AUTOSAR XML (schema 3.1.2)
package /Components/SWC_CurDrivFil
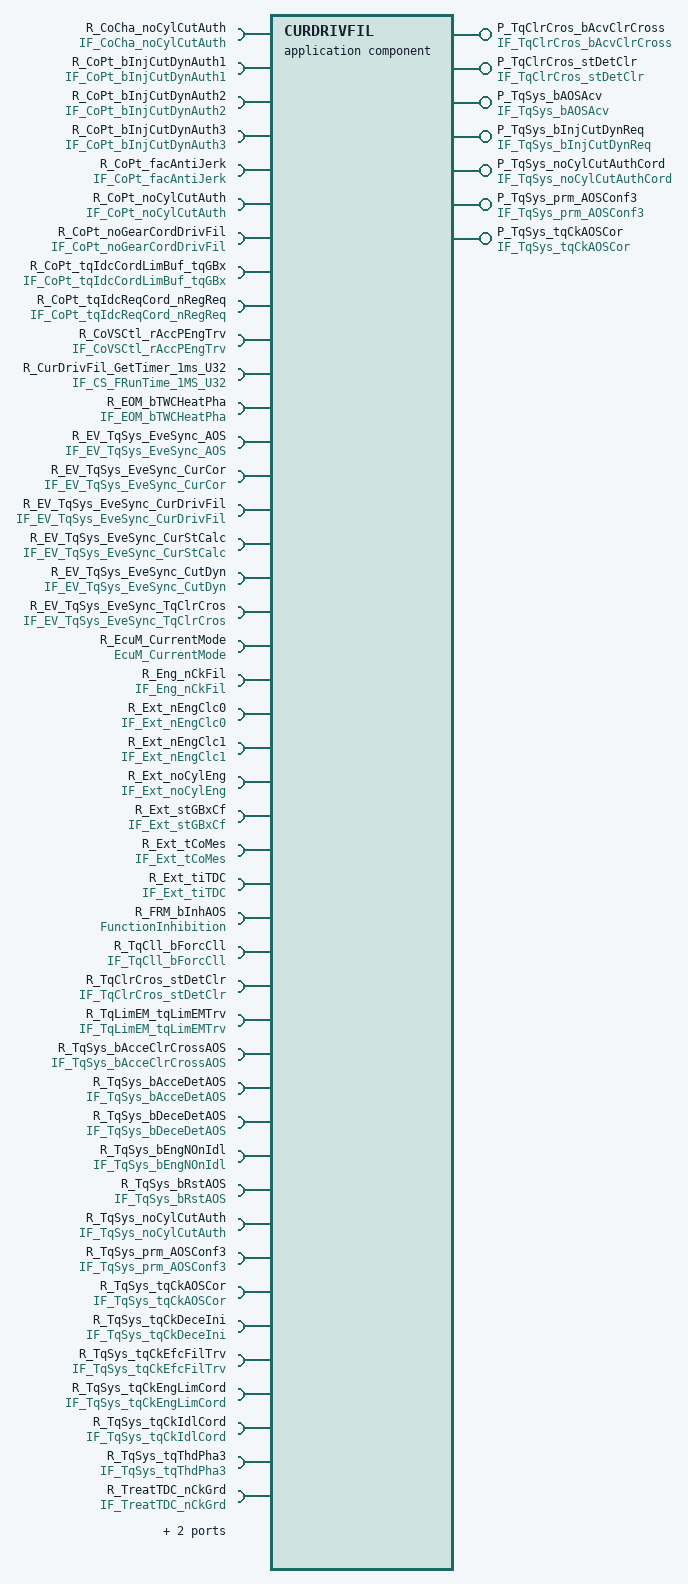
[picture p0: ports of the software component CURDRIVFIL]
  application software component type CURDRIVFIL  # CurDrivFil
    7 x provide port:
      P_TqClrCros_bAcvClrCross: unqueued-sender-com-spec{data-element=TqClrCros_bAcvClrCross, can-invalidate=false, init-value=ConstantValue}, provided-interface=IF_TqClrCros_bAcvClrCross  # Requirement: 01552_10_01787-CurDrivFil.I127(0)
      P_TqClrCros_stDetClr: unqueued-sender-com-spec{data-element=TqClrCros_stDetClr, can-invalidate=false, init-value=ConstantValue1}, provided-interface=IF_TqClrCros_stDetClr  # Requirement: 01552_10_01787-CurDrivFil.I128(0)
      P_TqSys_bAOSAcv: unqueued-sender-com-spec{data-element=TqSys_bAOSAcv, can-invalidate=false, init-value=ConstantValue3}, provided-interface=IF_TqSys_bAOSAcv  # Requirement: 01552_10_01787-CurDrivFil.I145(1)
      P_TqSys_bInjCutDynReq: unqueued-sender-com-spec{data-element=TqSys_bInjCutDynReq, can-invalidate=false, init-value=ConstantValue5}, provided-interface=IF_TqSys_bInjCutDynReq  # Requirement: 01552_10_01787-CurDrivFil.I132(1)
      P_TqSys_noCylCutAuthCord: unqueued-sender-com-spec{data-element=TqSys_noCylCutAuthCord, can-invalidate=false, init-value=ConstantValue7}, provided-interface=IF_TqSys_noCylCutAuthCord  # Requirement: 01552_10_01787-CurDrivFil.I131(1)
      P_TqSys_prm_AOSConf3: unqueued-sender-com-spec{data-element=TqSys_prm_AOSConf3, can-invalidate=false, init-value=ArrayConstantValue}, provided-interface=IF_TqSys_prm_AOSConf3  # Requirement: 01552_10_01787-CurDrivFil.I413(2)
      P_TqSys_tqCkAOSCor: unqueued-sender-com-spec{data-element=TqSys_tqCkAOSCor, can-invalidate=false, init-value=ConstantValue9}, provided-interface=IF_TqSys_tqCkAOSCor  # Requirement: 01552_10_01787-CurDrivFil.I146(1)
    46 x require port:
      R_CoCha_noCylCutAuth: unqueued-receiver-com-spec{data-element=CoCha_noCylCutAuth, init-value=ConstantValue11, resync-time=0}, required-interface=IF_CoCha_noCylCutAuth  # Requirement: 01552_10_01787-CurDrivFil.I133(0)
      R_CoPt_bInjCutDynAuth1: unqueued-receiver-com-spec{data-element=CoPt_bInjCutDynAuth1, init-value=ConstantValue13, resync-time=0}, required-interface=IF_CoPt_bInjCutDynAuth1  # Requirement: 01552_10_01787-CurDrivFil.I134(0)
      R_CoPt_bInjCutDynAuth2: unqueued-receiver-com-spec{data-element=CoPt_bInjCutDynAuth2, init-value=ConstantValue15, resync-time=0}, required-interface=IF_CoPt_bInjCutDynAuth2  # Requirement: 01552_10_01787-CurDrivFil.I135(0)
      R_CoPt_bInjCutDynAuth3: unqueued-receiver-com-spec{data-element=CoPt_bInjCutDynAuth3, init-value=ConstantValue17, resync-time=0}, required-interface=IF_CoPt_bInjCutDynAuth3  # Requirement: 01552_10_01787-CurDrivFil.I136(0)
      R_CoPt_facAntiJerk: unqueued-receiver-com-spec{data-element=CoPt_facAntiJerk, init-value=ConstantValue19, resync-time=0}, required-interface=IF_CoPt_facAntiJerk  # Requirement: 01552_10_01787-CurDrivFil.I100(0)
      R_CoPt_noCylCutAuth: unqueued-receiver-com-spec{data-element=CoPt_noCylCutAuth, init-value=ConstantValue21, resync-time=0}, required-interface=IF_CoPt_noCylCutAuth  # Requirement: 01552_10_01787-CurDrivFil.I137(0)
      R_CoPt_noGearCordDrivFil: unqueued-receiver-com-spec{data-element=CoPt_noGearCordDrivFil, init-value=ConstantValue23, resync-time=0}, required-interface=IF_CoPt_noGearCordDrivFil  # Requirement: 01552_10_01787-CurDrivFil.I119(0)
      R_CoPt_tqIdcCordLimBuf_tqGBx: unqueued-receiver-com-spec{data-element=CoPt_tqIdcCordLimBuf_tqGBx, init-value=ConstantValue25, resync-time=0}, required-interface=IF_CoPt_tqIdcCordLimBuf_tqGBx  # Requirement: 01552_10_01787-CurDrivFil.I138(0)
      R_CoPt_tqIdcReqCord_nRegReq: unqueued-receiver-com-spec{data-element=CoPt_tqIdcReqCord_nRegReq, init-value=ConstantValue27, resync-time=0}, required-interface=IF_CoPt_tqIdcReqCord_nRegReq  # Requirement: 01552_10_01787-CurDrivFil.I105(0)
      R_CoVSCtl_rAccPEngTrv: unqueued-receiver-com-spec{data-element=CoVSCtl_rAccPEngTrv, init-value=ConstantValue29, resync-time=0}, required-interface=IF_CoVSCtl_rAccPEngTrv  # Requirement: 01552_10_01787-CurDrivFil.I120(0)
      R_CurDrivFil_GetTimer_1ms_U32: required-interface=IF_CS_FRunTime_1MS_U32
      R_EOM_bTWCHeatPha: unqueued-receiver-com-spec{data-element=EOM_bTWCHeatPha, init-value=ConstantValue31, resync-time=0}, required-interface=IF_EOM_bTWCHeatPha  # Requirement: 01552_10_01787-CurDrivFil.I121(0)
      R_EV_TqSys_EveSync_AOS: unqueued-receiver-com-spec{data-element=EV_TqSys_EveSync_AOS, init-value=ConstantValue33, resync-time=0}, required-interface=IF_EV_TqSys_EveSync_AOS
      R_EV_TqSys_EveSync_CurCor: unqueued-receiver-com-spec{data-element=EV_TqSys_EveSync_CurCor, init-value=ConstantValue35, resync-time=0}, required-interface=IF_EV_TqSys_EveSync_CurCor
      R_EV_TqSys_EveSync_CurDrivFil: unqueued-receiver-com-spec{data-element=EV_TqSys_EveSync_CurDrivFil, init-value=ConstantValue37, resync-time=0}, required-interface=IF_EV_TqSys_EveSync_CurDrivFil
      R_EV_TqSys_EveSync_CurStCalc: unqueued-receiver-com-spec{data-element=EV_TqSys_EveSync_CurStCalc, init-value=ConstantValue39, resync-time=0}, required-interface=IF_EV_TqSys_EveSync_CurStCalc
      R_EV_TqSys_EveSync_CutDyn: unqueued-receiver-com-spec{data-element=EV_TqSys_EveSync_CutDyn, init-value=ConstantValue41, resync-time=0}, required-interface=IF_EV_TqSys_EveSync_CutDyn
      R_EV_TqSys_EveSync_TqClrCros: unqueued-receiver-com-spec{data-element=EV_TqSys_EveSync_TqClrCros, init-value=ConstantValue43, resync-time=0}, required-interface=IF_EV_TqSys_EveSync_TqClrCros
      R_EcuM_CurrentMode: required-interface=EcuM_CurrentMode  # Requirement: 01552_09_00532-SSTG-C007(0)
      R_Eng_nCkFil: unqueued-receiver-com-spec{data-element=Eng_nCkFil, init-value=ConstantValue45, resync-time=0}, required-interface=IF_Eng_nCkFil  # Requirement: 01552_10_01787-CurDrivFil.I139(0)
      R_Ext_nEngClc0: unqueued-receiver-com-spec{data-element=Ext_nEngClc0, init-value=ConstantValue47, resync-time=0}, required-interface=IF_Ext_nEngClc0  # Requirement: 01552_10_01787-CurDrivFil.I102(0)
      R_Ext_nEngClc1: unqueued-receiver-com-spec{data-element=Ext_nEngClc1, init-value=ConstantValue49, resync-time=0}, required-interface=IF_Ext_nEngClc1  # Requirement: 01552_10_01787-CurDrivFil.I103(0)
      R_Ext_noCylEng: unqueued-receiver-com-spec{data-element=Ext_noCylEng, init-value=ConstantValue51, resync-time=0}, required-interface=IF_Ext_noCylEng  # Requirement: 01552_10_01787-CurDrivFil.I140(0)
      R_Ext_stGBxCf: unqueued-receiver-com-spec{data-element=Ext_stGBxCf, init-value=ConstantValue53, resync-time=0}, required-interface=IF_Ext_stGBxCf  # Requirement: 01552_10_01787-CurDrivFil.I101(0)
      R_Ext_tCoMes: unqueued-receiver-com-spec{data-element=Ext_tCoMes, init-value=ConstantValue55, resync-time=0}, required-interface=IF_Ext_tCoMes  # Requirement: 01552_10_01787-CurDrivFil.I112(0)
      R_Ext_tiTDC: unqueued-receiver-com-spec{data-element=Ext_tiTDC, init-value=ConstantValue57, resync-time=0}, required-interface=IF_Ext_tiTDC  # Requirement: 01552_10_01787-CurDrivFil.I113(0)
      R_FRM_bInhAOS: required-interface=FunctionInhibition  # Requirement: 01552_10_01787-CurDrivFil.I700(0)
      R_TqCll_bForcCll: unqueued-receiver-com-spec{data-element=TqCll_bForcCll, init-value=ConstantValue59, resync-time=0}, required-interface=IF_TqCll_bForcCll  # Requirement: 01552_10_01787-CurDrivFil.I141(0)
      R_TqClrCros_stDetClr: unqueued-receiver-com-spec{data-element=TqClrCros_stDetClr, init-value=ConstantValue61, resync-time=0}, required-interface=IF_TqClrCros_stDetClr  # Requirement: 01552_10_01787-CurDrivFil.I156(0)
      R_TqLimEM_tqLimEMTrv: unqueued-receiver-com-spec{data-element=TqLimEM_tqLimEMTrv, init-value=ConstantValue63, resync-time=0}, required-interface=IF_TqLimEM_tqLimEMTrv  # Requirement: 01552_10_01787-CurDrivFil.I155(1)
      R_TqSys_bAcceClrCrossAOS: unqueued-receiver-com-spec{data-element=TqSys_bAcceClrCrossAOS, init-value=ConstantValue65, resync-time=0}, required-interface=IF_TqSys_bAcceClrCrossAOS  # Requirement: 01552_10_01787-CurDrivFil.I124(0)
      R_TqSys_bAcceDetAOS: unqueued-receiver-com-spec{data-element=TqSys_bAcceDetAOS, init-value=ConstantValue67, resync-time=0}, required-interface=IF_TqSys_bAcceDetAOS  # Requirement: 01552_10_01787-CurDrivFil.I125(0)
      R_TqSys_bDeceDetAOS: unqueued-receiver-com-spec{data-element=TqSys_bDeceDetAOS, init-value=ConstantValue69, resync-time=0}, required-interface=IF_TqSys_bDeceDetAOS  # Requirement: 01552_10_01787-CurDrivFil.I126(0)
      R_TqSys_bEngNOnIdl: unqueued-receiver-com-spec{data-element=TqSys_bEngNOnIdl, init-value=ConstantValue71, resync-time=0}, required-interface=IF_TqSys_bEngNOnIdl  # Requirement: 01552_10_01787-CurDrivFil.I109(0)
      R_TqSys_bRstAOS: unqueued-receiver-com-spec{data-element=TqSys_bRstAOS, init-value=ConstantValue73, resync-time=0}, required-interface=IF_TqSys_bRstAOS  # Requirement: 01552_10_01787-CurDrivFil.I147(0)
      R_TqSys_noCylCutAuth: unqueued-receiver-com-spec{data-element=TqSys_noCylCutAuth, init-value=ConstantValue75, resync-time=0}, required-interface=IF_TqSys_noCylCutAuth  # Requirement: 01552_10_01787-CurDrivFil.I143(0)
      R_TqSys_prm_AOSConf3: unqueued-receiver-com-spec{data-element=TqSys_prm_AOSConf3, init-value=ArrayConstantValue, resync-time=0}, required-interface=IF_TqSys_prm_AOSConf3  # Requirement: 01552_10_01787-CurDrivFil.I154(0)
      R_TqSys_tqCkAOSCor: unqueued-receiver-com-spec{data-element=TqSys_tqCkAOSCor, init-value=ConstantValue77, resync-time=0}, required-interface=IF_TqSys_tqCkAOSCor  # Requirement: 01552_10_01787-CurDrivFil.I157(0)
      R_TqSys_tqCkDeceIni: unqueued-receiver-com-spec{data-element=TqSys_tqCkDeceIni, init-value=ConstantValue79, resync-time=0}, required-interface=IF_TqSys_tqCkDeceIni  # Requirement: 01552_10_01787-CurDrivFil.I108(0)
      R_TqSys_tqCkEfcFilTrv: unqueued-receiver-com-spec{data-element=TqSys_tqCkEfcFilTrv, init-value=ConstantValue81, resync-time=0}, required-interface=IF_TqSys_tqCkEfcFilTrv  # Requirement: 01552_10_01787-CurDrivFil.I129(0)
      R_TqSys_tqCkEngLimCord: unqueued-receiver-com-spec{data-element=TqSys_tqCkEngLimCord, init-value=ConstantValue83, resync-time=0}, required-interface=IF_TqSys_tqCkEngLimCord  # Requirement: 01552_10_01787-CurDrivFil.I107(1)
      R_TqSys_tqCkIdlCord: unqueued-receiver-com-spec{data-element=TqSys_tqCkIdlCord, init-value=ConstantValue85, resync-time=0}, required-interface=IF_TqSys_tqCkIdlCord  # Requirement: 01552_10_01787-CurDrivFil.I106(0)
      R_TqSys_tqThdPha3: unqueued-receiver-com-spec{data-element=TqSys_tqThdPha3, init-value=ConstantValue87, resync-time=0}, required-interface=IF_TqSys_tqThdPha3  # Requirement: 01552_10_01787-CurDrivFil.I130(0)
      R_TreatTDC_nCkGrd: unqueued-receiver-com-spec{data-element=TreatTDC_nCkGrd, init-value=ConstantValue89, resync-time=0}, required-interface=IF_TreatTDC_nCkGrd  # Requirement: 01552_10_01787-CurDrivFil.I111(0)
      R_UCE_stSt: required-interface=IF_UCE_stSt  # Requirement: 01552_09_00532-SSTG-C011(0)
      R_Veh_spdVeh: unqueued-receiver-com-spec{data-element=Veh_spdVeh, init-value=ConstantValue91, resync-time=0}, required-interface=IF_Veh_spdVeh  # Requirement: 01552_10_01787-CurDrivFil.I104(0)
  64 x constant specification:
    ArrayConstantValue
      value:
        array specification ArrayConstantValue: type=t_CurDrivFil_Tab6_S16
          6 x integer literal, all with type=DT_TqSys_prm_AOSConf3, value=0:
            Const
            Const{1..5}
    C_Boolean_False
      value:
        boolean literal C_Boolean_False: type=DT_TqSys_bAOSSlopAcv_irv, value=false
    C_SInt16_0
      value:
        integer literal C_SInt16_0: type=DT_TqSys_facCorIdlPha_irv, value=0
    C_SInt16_0101
      value:
        integer literal C_SInt16_0101: type=DT_TqSys_facSpd0AOS_irv, value=0
    C_SInt16_0103
      value:
        integer literal C_SInt16_0103: type=DT_TqSys_facTq2AOS_irv, value=0
    C_SInt16_0107
      value:
        integer literal C_SInt16_0107: type=DT_TqSys_facTq3AOS_irv, value=0
    C_SInt16_0109
      value:
        integer literal C_SInt16_0109: type=DT_TqSys_facTq1AOS_irv, value=0
    C_SInt16_0111
      value:
        integer literal C_SInt16_0111: type=DT_TqSys_facTq0AOS_irv, value=0
    C_SInt16_0113
      value:
        integer literal C_SInt16_0113: type=DT_TqSys_tqCkFilRawAOS_irv, value=0
    C_SInt16_0115
      value:
        integer literal C_SInt16_0115: type=DT_TqSys_facCorOxCHeatPha_irv, value=0
    C_SInt16_093
      value:
        integer literal C_SInt16_093: type=DT_TqSys_facSpd1AOS_irv, value=0
    C_SInt16_097
      value:
        integer literal C_SInt16_097: type=DT_TqSys_facCorGlbl_irv, value=0
    C_SInt16_099
      value:
        integer literal C_SInt16_099: type=DT_TqSys_nFil2AOS_irv, value=0
    C_UInt16_0
      value:
        integer literal C_UInt16_0: type=DT_TqSys_ctOfsAcvAOS_irv, value=0
    C_UInt16_0105
      value:
        integer literal C_UInt16_0105: type=DT_TqSys_ctIncAcvAOS_irv, value=0
    C_UInt16_095
      value:
        integer literal C_UInt16_095: type=DT_TqSys_ctIncDiAOS_irv, value=0
    C_UInt8_2
      value:
        integer literal C_UInt8_2: type=DT_TqSys_stAcceAOS_irv, value=2
    ConstantValue
      value:
        boolean literal ConstantValue: type=DT_TqClrCros_bAcvClrCross, value=false
    ConstantValue1
      value:
        integer literal ConstantValue1: type=DT_TqClrCros_stDetClr, value=0
    ConstantValue11
      value:
        integer literal ConstantValue11: type=DT_CoCha_noCylCutAuth, value=0
    ConstantValue13
      value:
        boolean literal ConstantValue13: type=DT_CoPt_bInjCutDynAuth1, value=false
    ConstantValue15
      value:
        boolean literal ConstantValue15: type=DT_CoPt_bInjCutDynAuth2, value=false
    ConstantValue17
      value:
        boolean literal ConstantValue17: type=DT_CoPt_bInjCutDynAuth3, value=false
    ConstantValue19
      value:
        integer literal ConstantValue19: type=DT_CoPt_facAntiJerk, value=0
    ConstantValue21
      value:
        integer literal ConstantValue21: type=DT_CoPt_noCylCutAuth, value=0
    ConstantValue23
      value:
        integer literal ConstantValue23: type=DT_CoPt_noGearCordDrivFil, value=0
    ConstantValue25
      value:
        integer literal ConstantValue25: type=DT_CoPt_tqIdcCordLimBuf_tqGBx, value=0
    ConstantValue27
      value:
        integer literal ConstantValue27: type=DT_CoPt_tqIdcReqCord_nRegReq, value=0
    ConstantValue29
      value:
        integer literal ConstantValue29: type=DT_CoVSCtl_rAccPEngTrv, value=0
    ConstantValue3
      value:
        boolean literal ConstantValue3: type=DT_TqSys_bAOSAcv, value=false
    ConstantValue31
      value:
        boolean literal ConstantValue31: type=DT_EOM_bTWCHeatPha, value=false
    ConstantValue33
      value:
        integer literal ConstantValue33: type=DT_EV_TqSys_EveSync_AOS, value=0
    ConstantValue35
      value:
        integer literal ConstantValue35: type=DT_EV_TqSys_EveSync_CurCor, value=0
    ConstantValue37
      value:
        integer literal ConstantValue37: type=DT_EV_TqSys_EveSync_CurDrivFil, value=0
    ConstantValue39
      value:
        integer literal ConstantValue39: type=DT_EV_TqSys_EveSync_CurStCalc, value=0
    ConstantValue41
      value:
        integer literal ConstantValue41: type=DT_EV_TqSys_EveSync_CutDyn, value=0
    ConstantValue43
      value:
        integer literal ConstantValue43: type=DT_EV_TqSys_EveSync_TqClrCros, value=0
    ConstantValue45
      value:
        integer literal ConstantValue45: type=DT_Eng_nCkFil, value=0
    ConstantValue47
      value:
        integer literal ConstantValue47: type=DT_Ext_nEngClc0, value=0
    ConstantValue49
      value:
        integer literal ConstantValue49: type=DT_Ext_nEngClc1, value=0
    ConstantValue5
      value:
        boolean literal ConstantValue5: type=DT_TqSys_bInjCutDynReq, value=false
    ConstantValue51
      value:
        integer literal ConstantValue51: type=DT_Ext_noCylEng, value=1
    ConstantValue53
      value:
        integer literal ConstantValue53: type=DT_Ext_stGBxCf, value=0
    ConstantValue55
      value:
        integer literal ConstantValue55: type=DT_Ext_tCoMes, value=20
    ConstantValue57
      value:
        integer literal ConstantValue57: type=DT_Ext_tiTDC, value=100
    ConstantValue59
      value:
        boolean literal ConstantValue59: type=DT_TqCll_bForcCll, value=false
    ConstantValue61
      value:
        integer literal ConstantValue61: type=DT_TqClrCros_stDetClr, value=0
    ConstantValue63
      value:
        integer literal ConstantValue63: type=DT_TqLimEM_tqLimEMTrv, value=0
    ConstantValue65
      value:
        boolean literal ConstantValue65: type=DT_TqSys_bAcceClrCrossAOS, value=false
    ConstantValue67
      value:
        boolean literal ConstantValue67: type=DT_TqSys_bAcceDetAOS, value=false
    ConstantValue69
      value:
        boolean literal ConstantValue69: type=DT_TqSys_bDeceDetAOS, value=false
    ConstantValue7
      value:
        integer literal ConstantValue7: type=DT_TqSys_noCylCutAuthCord, value=0
    ConstantValue71
      value:
        boolean literal ConstantValue71: type=DT_TqSys_bEngNOnIdl, value=true
    ConstantValue73
      value:
        boolean literal ConstantValue73: type=DT_TqSys_bRstAOS, value=false
    ConstantValue75
      value:
        integer literal ConstantValue75: type=DT_TqSys_noCylCutAuth, value=0
    ConstantValue77
      value:
        integer literal ConstantValue77: type=DT_TqSys_tqCkAOSCor, value=0
    ConstantValue79
      value:
        integer literal ConstantValue79: type=DT_TqSys_tqCkDeceIni, value=0
    ConstantValue81
      value:
        integer literal ConstantValue81: type=DT_TqSys_tqCkEfcFilTrv, value=0
    ConstantValue83
      value:
        integer literal ConstantValue83: type=DT_TqSys_tqCkEngLimCord, value=0
    ConstantValue85
      value:
        integer literal ConstantValue85: type=DT_TqSys_tqCkIdlCord, value=0
    ConstantValue87
      value:
        integer literal ConstantValue87: type=DT_TqSys_tqThdPha3, value=0
    ConstantValue89
      value:
        integer literal ConstantValue89: type=DT_TreatTDC_nCkGrd, value=0
    ConstantValue9
      value:
        integer literal ConstantValue9: type=DT_TqSys_tqCkAOSCor, value=0
    ConstantValue91
      value:
        integer literal ConstantValue91: type=DT_Veh_spdVeh, value=0
  internal behavior IB_CurDrivFil: component=CURDRIVFIL
    mode switch event EV_CurDrivFil_001_MSE: start-on-event=RE_CurDrivFil_001_MSE, activation=ENTRY, mode=R_EcuM_CurrentMode.currentMode.RUN
    6 x data received event, all with mode-dependency=dependent-on-mode=[R_UCE_stSt.RCD_Mode.COM_LATCH, R_UCE_stSt.RCD_Mode.INTERNAL_PARTIAL_WAKEUP, R_UCE_stSt.RCD_Mode.INTERNAL_PARTIAL_WAKEUP_APC, R_UCE_stSt.RCD_Mode.PARTIAL_WAKEUP, R_UCE_stSt.RCD_Mode.SHUTDOWN_PREPARATION, R_UCE_stSt.RCD_Mode.SHUTDOWN_PREPARATION_APC, R_UCE_stSt.RCD_Mode.TRANSITORY]:
      EV_TqSys_EveSync_CutDyn: start-on-event=RE_TqSys_EveSync_CutDyn, data=R_EV_TqSys_EveSync_CutDyn.EV_TqSys_EveSync_CutDyn
      EV_TqSys_EveSync_CurCor: start-on-event=RE_TqSys_EveSync_CurCor, data=R_EV_TqSys_EveSync_CurCor.EV_TqSys_EveSync_CurCor
      EV_TqSys_EveSync_TqClrCros: start-on-event=RE_TqSys_EveSync_TqClrCros, data=R_EV_TqSys_EveSync_TqClrCros.EV_TqSys_EveSync_TqClrCros
      EV_TqSys_EveSync_AOS: start-on-event=RE_TqSys_EveSync_AOS, data=R_EV_TqSys_EveSync_AOS.EV_TqSys_EveSync_AOS
      EV_TqSys_EveSync_CurStCalc: start-on-event=RE_TqSys_EveSync_CurStCalc, data=R_EV_TqSys_EveSync_CurStCalc.EV_TqSys_EveSync_CurStCalc
      EV_TqSys_EveSync_CurDrivFil: start-on-event=RE_TqSys_EveSync_CurDrivFil, data=R_EV_TqSys_EveSync_CurDrivFil.EV_TqSys_EveSync_CurDrivFil
    16 x inter runnable variable, all with sw-calibration-access=READ-WRITE, communication-approach=EXPLICIT:
      TqSys_ctOfsAcvAOS_irv: type=DT_TqSys_ctOfsAcvAOS_irv, init-value=C_UInt16_0
      TqSys_ctIncAcvAOS_irv: type=DT_TqSys_ctIncAcvAOS_irv, init-value=C_UInt16_0105
      TqSys_facTq2AOS_irv: type=DT_TqSys_facTq2AOS_irv, init-value=C_SInt16_0103
      TqSys_bAOSSlopAcv_irv: type=DT_TqSys_bAOSSlopAcv_irv, init-value=C_Boolean_False
      TqSys_tqCkFilRawAOS_irv: type=DT_TqSys_tqCkFilRawAOS_irv, init-value=C_SInt16_0113
      TqSys_facTq3AOS_irv: type=DT_TqSys_facTq3AOS_irv, init-value=C_SInt16_0107
      TqSys_nFil2AOS_irv: type=DT_TqSys_nFil2AOS_irv, init-value=C_SInt16_099
      TqSys_facCorIdlPha_irv: type=DT_TqSys_facCorIdlPha_irv, init-value=C_SInt16_0
      TqSys_facTq1AOS_irv: type=DT_TqSys_facTq1AOS_irv, init-value=C_SInt16_0109
      TqSys_ctIncDiAOS_irv: type=DT_TqSys_ctIncDiAOS_irv, init-value=C_UInt16_095
      TqSys_facCorGlbl_irv: type=DT_TqSys_facCorGlbl_irv, init-value=C_SInt16_097
      TqSys_stAcceAOS_irv: type=DT_TqSys_stAcceAOS_irv, init-value=C_UInt8_2
      TqSys_facCorOxCHeatPha_irv: type=DT_TqSys_facCorOxCHeatPha_irv, init-value=C_SInt16_0115
      TqSys_facSpd0AOS_irv: type=DT_TqSys_facSpd0AOS_irv, init-value=C_SInt16_0101
      TqSys_facSpd1AOS_irv: type=DT_TqSys_facSpd1AOS_irv, init-value=C_SInt16_093
      TqSys_facTq0AOS_irv: type=DT_TqSys_facTq0AOS_irv, init-value=C_SInt16_0111
    7 x runnable:
      RE_TqSys_EveSync_CurStCalc: read-variable=TqSys_nFil2AOS_irv, written-variable=[TqSys_nFil2AOS_irv, TqSys_stAcceAOS_irv]
        12 x data receive point:
          dr_TqSys_bAcceDetAOS: data-element=R_TqSys_bAcceDetAOS.TqSys_bAcceDetAOS
          dr_TqSys_bDeceDetAOS: data-element=R_TqSys_bDeceDetAOS.TqSys_bDeceDetAOS
          dr_TqSys_tqThdPha3: data-element=R_TqSys_tqThdPha3.TqSys_tqThdPha3
          dr_TqSys_tqCkDeceIni: data-element=R_TqSys_tqCkDeceIni.TqSys_tqCkDeceIni
          dr_TqLimEM_tqLimEMTrv: data-element=R_TqLimEM_tqLimEMTrv.TqLimEM_tqLimEMTrv
          dr_Ext_tiTDC: data-element=R_Ext_tiTDC.Ext_tiTDC
          dr_TqSys_bAcceClrCrossAOS: data-element=R_TqSys_bAcceClrCrossAOS.TqSys_bAcceClrCrossAOS
          dr_TqClrCros_stDetClr: data-element=R_TqClrCros_stDetClr.TqClrCros_stDetClr
          dr_CoPt_noGearCordDrivFil: data-element=R_CoPt_noGearCordDrivFil.CoPt_noGearCordDrivFil
          dr_TqSys_tqCkAOSCor: data-element=R_TqSys_tqCkAOSCor.TqSys_tqCkAOSCor
          dr_Ext_nEngClc0: data-element=R_Ext_nEngClc0.Ext_nEngClc0
          dr_TqSys_tqCkEfcFilTrv: data-element=R_TqSys_tqCkEfcFilTrv.TqSys_tqCkEfcFilTrv
        sync call ssp_GetTimer_1ms_U32: operation=R_CurDrivFil_GetTimer_1ms_U32.GetTimer_1ms_U32
      RE_CurDrivFil_001_MSE: written-variable=[TqSys_facCorIdlPha_irv, TqSys_facTq0AOS_irv, TqSys_facTq2AOS_irv, TqSys_stAcceAOS_irv, TqSys_ctOfsAcvAOS_irv, TqSys_facTq1AOS_irv, TqSys_bAOSSlopAcv_irv, TqSys_nFil2AOS_irv, TqSys_tqCkFilRawAOS_irv, TqSys_facCorGlbl_irv, TqSys_facTq3AOS_irv, TqSys_facSpd1AOS_irv, TqSys_ctIncDiAOS_irv, TqSys_facSpd0AOS_irv, TqSys_facCorOxCHeatPha_irv, TqSys_ctIncAcvAOS_irv]  # RE_062095_10ms_init
        7 x data send point:
          ds_TqSys_bInjCutDynReq: data-element=P_TqSys_bInjCutDynReq.TqSys_bInjCutDynReq
          ds_TqSys_tqCkAOSCor: data-element=P_TqSys_tqCkAOSCor.TqSys_tqCkAOSCor
          ds_TqClrCros_bAcvClrCross: data-element=P_TqClrCros_bAcvClrCross.TqClrCros_bAcvClrCross
          ds_TqClrCros_stDetClr: data-element=P_TqClrCros_stDetClr.TqClrCros_stDetClr
          ds_TqSys_bAOSAcv: data-element=P_TqSys_bAOSAcv.TqSys_bAOSAcv
          ds_TqSys_prm_AOSConf3: data-element=P_TqSys_prm_AOSConf3.TqSys_prm_AOSConf3
          ds_TqSys_noCylCutAuthCord: data-element=P_TqSys_noCylCutAuthCord.TqSys_noCylCutAuthCord
        sync call ssp_GetTimer_1ms_U32: operation=R_CurDrivFil_GetTimer_1ms_U32.GetTimer_1ms_U32
      RE_TqSys_EveSync_CurDrivFil: read-variable=[TqSys_facCorGlbl_irv, TqSys_stAcceAOS_irv], written-variable=[TqSys_facTq2AOS_irv, TqSys_facCorGlbl_irv, TqSys_ctOfsAcvAOS_irv, TqSys_facTq3AOS_irv, TqSys_facTq0AOS_irv, TqSys_facCorIdlPha_irv, TqSys_facSpd0AOS_irv, TqSys_facTq1AOS_irv, TqSys_stAcceAOS_irv, TqSys_facSpd1AOS_irv, TqSys_ctIncDiAOS_irv, TqSys_ctIncAcvAOS_irv, TqSys_facCorOxCHeatPha_irv, TqSys_bAOSSlopAcv_irv]
        11 x data receive point:
          dr_TqSys_tqCkDeceIni: data-element=R_TqSys_tqCkDeceIni.TqSys_tqCkDeceIni
          dr_Veh_spdVeh: data-element=R_Veh_spdVeh.Veh_spdVeh
          dr_CoPt_noGearCordDrivFil: data-element=R_CoPt_noGearCordDrivFil.CoPt_noGearCordDrivFil
          dr_TreatTDC_nCkGrd: data-element=R_TreatTDC_nCkGrd.TreatTDC_nCkGrd
          dr_TqSys_prm_AOSConf3: data-element=R_TqSys_prm_AOSConf3.TqSys_prm_AOSConf3
          dr_EOM_bTWCHeatPha: data-element=R_EOM_bTWCHeatPha.EOM_bTWCHeatPha
          dr_Ext_nEngClc0: data-element=R_Ext_nEngClc0.Ext_nEngClc0
          dr_TqSys_tqCkEngLimCord: data-element=R_TqSys_tqCkEngLimCord.TqSys_tqCkEngLimCord
          dr_TqSys_bEngNOnIdl: data-element=R_TqSys_bEngNOnIdl.TqSys_bEngNOnIdl
          dr_CoVSCtl_rAccPEngTrv: data-element=R_CoVSCtl_rAccPEngTrv.CoVSCtl_rAccPEngTrv
          dr_Ext_tiTDC: data-element=R_Ext_tiTDC.Ext_tiTDC
        data send point ds_TqSys_prm_AOSConf3: data-element=P_TqSys_prm_AOSConf3.TqSys_prm_AOSConf3
        sync call ssp_GetTimer_1ms_U32: operation=R_CurDrivFil_GetTimer_1ms_U32.GetTimer_1ms_U32
      RE_TqSys_EveSync_CurCor: read-variable=[TqSys_stAcceAOS_irv, TqSys_ctIncDiAOS_irv, TqSys_bAOSSlopAcv_irv, TqSys_nFil2AOS_irv, TqSys_ctIncAcvAOS_irv, TqSys_tqCkFilRawAOS_irv, TqSys_facCorGlbl_irv, TqSys_ctOfsAcvAOS_irv, TqSys_facCorIdlPha_irv, TqSys_facCorOxCHeatPha_irv], written-variable=[TqSys_nFil2AOS_irv, TqSys_tqCkFilRawAOS_irv, TqSys_facCorGlbl_irv, TqSys_facCorIdlPha_irv, TqSys_facCorOxCHeatPha_irv]
        11 x data receive point:
          dr_Ext_tCoMes: data-element=R_Ext_tCoMes.Ext_tCoMes
          dr_Ext_nEngClc0: data-element=R_Ext_nEngClc0.Ext_nEngClc0
          dr_TqLimEM_tqLimEMTrv: data-element=R_TqLimEM_tqLimEMTrv.TqLimEM_tqLimEMTrv
          dr_CoPt_facAntiJerk: data-element=R_CoPt_facAntiJerk.CoPt_facAntiJerk
          dr_Ext_tiTDC: data-element=R_Ext_tiTDC.Ext_tiTDC
          dr_CoPt_tqIdcReqCord_nRegReq: data-element=R_CoPt_tqIdcReqCord_nRegReq.CoPt_tqIdcReqCord_nRegReq
          dr_TqSys_tqCkIdlCord: data-element=R_TqSys_tqCkIdlCord.TqSys_tqCkIdlCord
          dr_CoPt_noGearCordDrivFil: data-element=R_CoPt_noGearCordDrivFil.CoPt_noGearCordDrivFil
          dr_TqSys_bRstAOS: data-element=R_TqSys_bRstAOS.TqSys_bRstAOS
          dr_TqSys_tqCkDeceIni: data-element=R_TqSys_tqCkDeceIni.TqSys_tqCkDeceIni
          dr_Ext_stGBxCf: data-element=R_Ext_stGBxCf.Ext_stGBxCf
        data send point ds_TqSys_tqCkAOSCor: data-element=P_TqSys_tqCkAOSCor.TqSys_tqCkAOSCor
        data send point ds_TqSys_bAOSAcv: data-element=P_TqSys_bAOSAcv.TqSys_bAOSAcv
        sync call ssp_FRM_bInhAOS: operation=R_FRM_bInhAOS.GetFunctionPermission
        sync call ssp_GetTimer_1ms_U32: operation=R_CurDrivFil_GetTimer_1ms_U32.GetTimer_1ms_U32
      RE_TqSys_EveSync_CutDyn: read-variable=TqSys_tqCkFilRawAOS_irv, written-variable=TqSys_tqCkFilRawAOS_irv
        15 x data receive point:
          dr_Ext_tiTDC: data-element=R_Ext_tiTDC.Ext_tiTDC
          dr_CoPt_tqIdcCordLimBuf_tqGBx: data-element=R_CoPt_tqIdcCordLimBuf_tqGBx.CoPt_tqIdcCordLimBuf_tqGBx
          dr_TqSys_noCylCutAuth: data-element=R_TqSys_noCylCutAuth.TqSys_noCylCutAuth
          dr_CoPt_noCylCutAuth: data-element=R_CoPt_noCylCutAuth.CoPt_noCylCutAuth
          dr_CoPt_noGearCordDrivFil: data-element=R_CoPt_noGearCordDrivFil.CoPt_noGearCordDrivFil
          dr_Eng_nCkFil: data-element=R_Eng_nCkFil.Eng_nCkFil
          dr_TqSys_tqCkDeceIni: data-element=R_TqSys_tqCkDeceIni.TqSys_tqCkDeceIni
          dr_CoPt_bInjCutDynAuth3: data-element=R_CoPt_bInjCutDynAuth3.CoPt_bInjCutDynAuth3
          dr_TqSys_tqCkEfcFilTrv: data-element=R_TqSys_tqCkEfcFilTrv.TqSys_tqCkEfcFilTrv
          dr_TqCll_bForcCll: data-element=R_TqCll_bForcCll.TqCll_bForcCll
          dr_CoVSCtl_rAccPEngTrv: data-element=R_CoVSCtl_rAccPEngTrv.CoVSCtl_rAccPEngTrv
          dr_Ext_noCylEng: data-element=R_Ext_noCylEng.Ext_noCylEng
          dr_CoPt_bInjCutDynAuth1: data-element=R_CoPt_bInjCutDynAuth1.CoPt_bInjCutDynAuth1
          dr_CoPt_bInjCutDynAuth2: data-element=R_CoPt_bInjCutDynAuth2.CoPt_bInjCutDynAuth2
          dr_CoCha_noCylCutAuth: data-element=R_CoCha_noCylCutAuth.CoCha_noCylCutAuth
        data send point ds_TqSys_bInjCutDynReq: data-element=P_TqSys_bInjCutDynReq.TqSys_bInjCutDynReq
        data send point ds_TqSys_noCylCutAuthCord: data-element=P_TqSys_noCylCutAuthCord.TqSys_noCylCutAuthCord
        sync call ssp_GetTimer_1ms_U32: operation=R_CurDrivFil_GetTimer_1ms_U32.GetTimer_1ms_U32
      RE_TqSys_EveSync_TqClrCros: read-variable=TqSys_tqCkFilRawAOS_irv, written-variable=TqSys_tqCkFilRawAOS_irv
        6 x data receive point:
          dr_CoPt_noGearCordDrivFil: data-element=R_CoPt_noGearCordDrivFil.CoPt_noGearCordDrivFil
          dr_Ext_tiTDC: data-element=R_Ext_tiTDC.Ext_tiTDC
          dr_Ext_nEngClc0: data-element=R_Ext_nEngClc0.Ext_nEngClc0
          dr_Ext_nEngClc1: data-element=R_Ext_nEngClc1.Ext_nEngClc1
          dr_TqSys_tqCkEfcFilTrv: data-element=R_TqSys_tqCkEfcFilTrv.TqSys_tqCkEfcFilTrv
          dr_TqSys_tqThdPha3: data-element=R_TqSys_tqThdPha3.TqSys_tqThdPha3
        data send point ds_TqClrCros_stDetClr: data-element=P_TqClrCros_stDetClr.TqClrCros_stDetClr
        data send point ds_TqClrCros_bAcvClrCross: data-element=P_TqClrCros_bAcvClrCross.TqClrCros_bAcvClrCross
        sync call ssp_GetTimer_1ms_U32: operation=R_CurDrivFil_GetTimer_1ms_U32.GetTimer_1ms_U32
      RE_TqSys_EveSync_AOS: read-variable=[TqSys_facTq0AOS_irv, TqSys_facSpd0AOS_irv, TqSys_facSpd1AOS_irv, TqSys_facTq2AOS_irv, TqSys_facTq3AOS_irv, TqSys_facTq1AOS_irv], written-variable=[TqSys_facTq0AOS_irv, TqSys_nFil2AOS_irv, TqSys_facSpd0AOS_irv, TqSys_tqCkFilRawAOS_irv, TqSys_facSpd1AOS_irv, TqSys_facTq2AOS_irv, TqSys_facTq3AOS_irv, TqSys_facTq1AOS_irv]
        data receive point dr_Ext_nEngClc0: data-element=R_Ext_nEngClc0.Ext_nEngClc0
        data receive point dr_Ext_nEngClc1: data-element=R_Ext_nEngClc1.Ext_nEngClc1
        sync call ssp_GetTimer_1ms_U32: operation=R_CurDrivFil_GetTimer_1ms_U32.GetTimer_1ms_U32
  swc implementation Imp_CurDrivFil: programming-language=C, behavior=IB_CurDrivFil
    code-descriptors:
      code CodeDescriptor: type=SRC
        9 x xfile:
          CURDRIVFIL_Aos_Func_Agr_c: url=CURDRIVFIL_Aos_Func_Agr.c
          CURDRIVFIL_Detect_Clr_Cross_c: url=CURDRIVFIL_Detect_Clr_Cross.c
          CURDRIVFIL_Curatif_Param_c: url=CURDRIVFIL_Curatif_Param.c
          CURDRIVFIL_Coor_Cut_Dyn_Sel_c: url=CURDRIVFIL_Coor_Cut_Dyn_Sel.c
          CURDRIVFIL_Final_Curat_Corr_c: url=CURDRIVFIL_Final_Curat_Corr.c
          CurDrivFil_c: url=CurDrivFil.c
          CurDrivFil_MemMap_h: url=CurDrivFil_MemMap.h
          CurDrivFil_h: url=CurDrivFil.h
          CURDRIVFIL_Accel_State_c: url=CURDRIVFIL_Accel_State.c
package /Components/SWC_CurDrivFil/CurDrivFil_IRVDatatypes
  boolean type DT_TqSys_bAOSSlopAcv_irv: base-type=boolean
  15 x integer type:
    DT_TqSys_ctIncAcvAOS_irv: base-type=uint16, lower-limit=0, upper-limit=65535
    DT_TqSys_ctIncDiAOS_irv: base-type=uint16, lower-limit=0, upper-limit=65535
    DT_TqSys_ctOfsAcvAOS_irv: base-type=uint16, lower-limit=0, upper-limit=65535
    DT_TqSys_facCorGlbl_irv: base-type=int16, lower-limit=-32768, upper-limit=32767
    DT_TqSys_facCorIdlPha_irv: base-type=int16, lower-limit=-32768, upper-limit=32767
    DT_TqSys_facCorOxCHeatPha_irv: base-type=int16, lower-limit=-32768, upper-limit=32767
    DT_TqSys_facSpd0AOS_irv: base-type=int16, lower-limit=-32768, upper-limit=32767
    DT_TqSys_facSpd1AOS_irv: base-type=int16, lower-limit=-32768, upper-limit=32767
    DT_TqSys_facTq{0..3}AOS_irv: base-type=int16, lower-limit=-32768, upper-limit=32767
    DT_TqSys_nFil2AOS_irv: base-type=int16, lower-limit=-32768, upper-limit=32767
    DT_TqSys_stAcceAOS_irv: base-type=uint8, lower-limit=0, upper-limit=255
    DT_TqSys_tqCkFilRawAOS_irv: base-type=int16, lower-limit=-32768, upper-limit=32767
